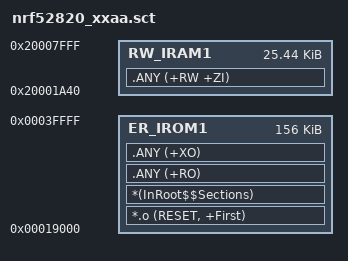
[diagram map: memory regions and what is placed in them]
; *************************************************************
; *** Scatter-Loading Description File generated by uVision ***
; *************************************************************

LR_IROM1 0x00019000 0x00027000  {    ; load region size_region
  ER_IROM1 0x00019000 0x00027000  {  ; load address = execution address
   *.o (RESET, +First)
   *(InRoot$$Sections)
   .ANY (+RO)
   .ANY (+XO)
  }
  RW_IRAM1 0x20001A40 0x000065C0  {  ; RW data
   .ANY (+RW +ZI)
  }
}

